# WS53 register map
File version: 0.1.0-experimental
Registers are 32-bit, read-write, no defined reset value unless marked. A register's access mark holds for its fields unless they carry their own. Offsets are from the block's base; [hi:lo] are bit positions; {n}, {i} and the like mark numbered series.

## SFC_CFG
Base 0x53000000
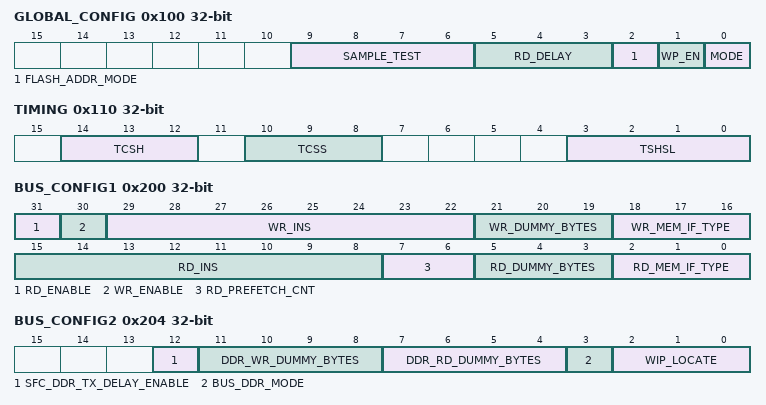
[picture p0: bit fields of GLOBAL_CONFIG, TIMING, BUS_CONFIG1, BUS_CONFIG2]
0x100 GLOBAL_CONFIG
  [9:6] SAMPLE_TEST — SDK DDR sampling-point selector; layout only, DDR operation unqualified
  [5:3] RD_DELAY — SPI read data delay: 000=0.5~1clk; 001=1~1.5clk; etc.
  [2] FLASH_ADDR_MODE — Address mode: 0=3byte; 1=4byte. NOTE: write has no effect when CMD_CONFIG[start]=1
    0=Addr3Byte (3-byte addressing); 1=Addr4Byte (4-byte addressing)
  [1] WP_EN — Hardware write protect: 0=disabled; 1=enabled
  [0] MODE — SPI mode: 0=Mode0; 1=Mode3
    0=SPI Mode 0 (CPOL=0, CPHA=0); 1=SPI Mode 3 (CPOL=1, CPHA=1)
0x110 TIMING
  [14:12] TCSH — CS hold time: (n+1) clock cycles
  [10:8] TCSS — CS setup time: (n+1) clock cycles
  [3:0] TSHSL — Inter-operation delay: (n+2) clock cycles
0x200 BUS_CONFIG1
  [31] RD_ENABLE — Bus read enable
  [30] WR_ENABLE — Bus write enable
  [29:22] WR_INS — Write instruction code
  [21:19] WR_DUMMY_BYTES — Write dummy bytes
  [18:16] WR_MEM_IF_TYPE — Write SPI interface type
  [15:8] RD_INS — Read instruction code
  [7:6] RD_PREFETCH_CNT — Read prefetch count: 00=none; 01=1clk; 10=2clk; 11=3clk
  [5:3] RD_DUMMY_BYTES — Read dummy bytes: 000=0; 001=1; etc.
  [2:0] RD_MEM_IF_TYPE — Read SPI interface type: 000=Standard; 001=Dual I/O; 010=Dual-IO; 101=Quad-Input; 110=Quad-IO
0x204 BUS_CONFIG2
  [12] SFC_DDR_TX_DELAY_ENABLE
  [11:8] DDR_WR_DUMMY_BYTES
  [7:4] DDR_RD_DUMMY_BYTES
  [3] BUS_DDR_MODE — SDK DDR bus-mode bit; layout only, DDR operation unqualified
  [2:0] WIP_LOCATE — WIP bit position in Flash status register: 000=bit0; etc.
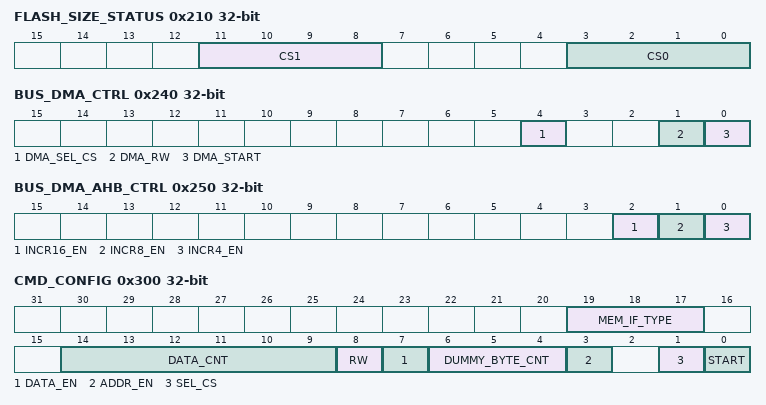
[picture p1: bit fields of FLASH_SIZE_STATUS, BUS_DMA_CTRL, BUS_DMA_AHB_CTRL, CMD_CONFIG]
0x210 FLASH_SIZE_STATUS ro
  [11:8] CS1
  [3:0] CS0 — SDK alias-size encoding; not a JEDEC capacity measurement
{0x214+4i} FLASH_BASE_STATUS[{i}] (i=0..1) ro
  [31:16] VALUE — Mapping byte address high16; low16 reserved. SDK supplies address shifted right16 to this field
0x220 FLASH_ALIAS_STATUS ro
  [0] ALIAS_CS
0x240 BUS_DMA_CTRL
  [4] DMA_SEL_CS — DMA chip select: 0=CS0; 1=CS1
  [1] DMA_RW — DMA direction: 0=write; 1=read
  [0] DMA_START — SDK starts bus DMA by writing 1 and polls until hardware returns 0 after transfer completion per header. Source contract uses repeated volatile reads, not a read-clear operation; silicon side effects/timing unqualified. No abort, buffer-ownership or posted-write drain proof follows from zero
0x244 BUS_DMA_MEM_SADDR
  [31:0] DMA_MEM_SADDR — SDK writes caller RAM pointer as a 32-bit bus-DMA address. No supported RAM range, alias translation, cache policy or exclusive ownership is established by this register layout
0x248 BUS_DMA_FLASH_SADDR
  [31:0] DMA_FLASH_SADDR — DMA Flash start address
0x24C BUS_DMA_LEN
  [29:0] DMA_LEN — Thirty-bit DMA length-minus-one; SDK helper preserves upper bits but does not validate zero/oversize. Layout is not a buffer ownership or transfer-range guarantee
0x250 BUS_DMA_AHB_CTRL
  [2] INCR16_EN — INCR16 burst enable
  [1] INCR8_EN — INCR8 burst enable
  [0] INCR4_EN — INCR4 burst enable
0x300 CMD_CONFIG
  [19:17] MEM_IF_TYPE — SPI interface type: 000=Standard; 001=Dual; 010=Dual-IO; 101=Quad-Input; 110=Quad-IO
  [14:9] DATA_CNT — Six-bit length-minus-one for data-enabled commands: 1..64 bytes. Original SDK helper truncates size-1, including zero/oversize; caller validation is required. With data_en=0 this field is not a data request
  [8] RW — Data direction: 0=write; 1=read
  [7] DATA_EN — Data present: 0=no; 1=yes
  [6:4] DUMMY_BYTE_CNT — Dummy bytes: 000=0; 001=1; etc.
  [3] ADDR_EN — Address present: 0=no; 1=yes
  [1] SEL_CS — Chip select: 0=CS0; 1=CS1
  [0] START — SDK starts SPI transfer by writing 1 and polls until hardware returns 0 after transfer completion per header. Source contract uses repeated volatile reads, not a read-clear operation; silicon side effects/timing, write-while-busy and forced-clear semantics unqualified. Zero does not certify NOR WIP, cache coherence or bus drain
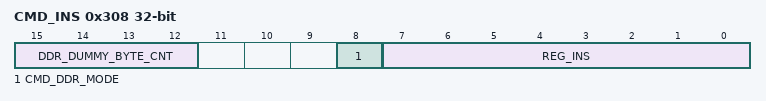
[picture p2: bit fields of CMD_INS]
0x308 CMD_INS
  [15:12] DDR_DUMMY_BYTE_CNT — SDK DDR dummy count; layout only, standard-SPI helpers preserve it
  [8] CMD_DDR_MODE — SDK command DDR bit; layout only, standard-SPI helpers preserve it
  [7:0] REG_INS — Instruction code
0x30C CMD_ADDR
  [29:0] CMD_ADDR — Operation address
0x400 CMD_DATABUF_0
  [31:0] CMD_DATABUF_0 — CPU command data buffer, also updated by completed reads. SDK uses ordinary volatile accesses without a source-level FIFO pop/read-clear operation; silicon side effects unverified. A previously buffered value is not a fresh Flash status/WIP observation: SDK issues a status command, waits command START, then reads this word
{0x400+4i} CMD_DATABUF_{i} (i=1..15)
  [31:0] CMD_DATABUF_{i} — Command data word {i}; SDK ordinary volatile read/write, hardware-read result after START polling. No source-level FIFO pop/read-clear; silicon side effects unverified. Old data is not fresh WIP
{0x1000+4i} FAPC_START_STATUS[{i}] (i=0..3) ro
  [31:8] ADDRESS — SDK writes byte address; bottom8 bits reserved
{0x1040+4i} FAPC_END_STATUS[{i}] (i=0..3) ro
  [31:8] ADDRESS — SDK region end address; bottom8 bits reserved
0x1180 FAPC_MODE_STATUS ro
  [7:0] MODES — Two bits per region: 0 normal, 2 decrypt per hal_fapc_set_region_mode; other values unqualified
0x1220 FAPC_LOCK_STATUS ro
  [3:0] LOCKED — Readback only; no one-way lock writes exposed
0x1300 LEA_LP_EN
  [0] LEA_LP_EN — AES low power: 0=disabled; 1=enabled
0x1304 LEA_DFX_INFO ro
  [31:0] LEA_DFX_INFO — AES DFX observation
0x1600 LEA_IV_VLD
  [0] LEA_IV_VLD — AES IV value valid (auto-clears after sync)
{0x1640+4i} FAPC_IV_START_STATUS[{i}] (i=0..3) ro
  [31:0] VALUE — ACPU IV start address per region; no IV/key contents exposed
